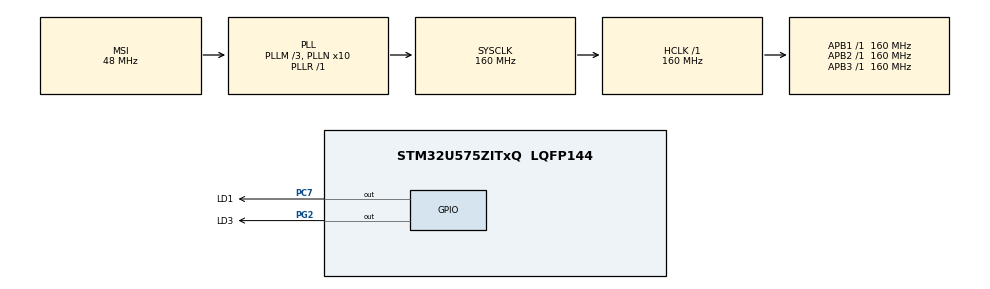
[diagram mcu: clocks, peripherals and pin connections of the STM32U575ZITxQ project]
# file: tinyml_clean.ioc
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CORTEX_M33_NS.userName=CORTEX_M33
Mcu.Family=STM32U5
Mcu.Name=STM32U575ZITxQ
Mcu.Package=LQFP144
NVIC.PriorityGroup=NVIC_PRIORITYGROUP_4
PC7.GPIO_Label=LD1
PC7.Signal=GPIO_Output
PG2.GPIO_Label=LD3
PG2.Signal=GPIO_Output
ProjectManager.HeapSize=0x800
ProjectManager.StackSize=0x800
ProjectManager.TargetToolchain=STM32CubeIDE
RCC.ADCCLockSelection=RCC_ADCDACCLKSOURCE_PLL2
RCC.ADCFreq_Value=160000000
RCC.AHBFreq_Value=160000000
RCC.APB1Freq_Value=160000000
RCC.APB1TimFreq_Value=160000000
RCC.APB2Freq_Value=160000000
RCC.APB2TimFreq_Value=160000000
RCC.APB3Freq_Value=160000000
RCC.CortexFreq_Value=160000000
RCC.EPOD_VALUE=48000000
RCC.HCLKFreq_Value=160000000
RCC.HSE_VALUE=16000000
RCC.HSI48_VALUE=48000000
RCC.HSI_VALUE=16000000
RCC.LSE_VALUE=32768
RCC.LSIDIV_VALUE=32000
RCC.MSIClockRange=RCC_MSIRANGE_0
RCC.MSI_VALUE=48000000
RCC.PLL1R=1
RCC.PLL2M=3
RCC.PLL2N=20
RCC.PLLM=3
RCC.PLLN=10
RCC.PWR_Regulator_Voltage_Scale=PWR_REGULATOR_VOLTAGE_SCALE1
RCC.SYSCLKFreq_VALUE=160000000
RCC.SYSCLKSource=RCC_SYSCLKSOURCE_PLLCLK
RCC.USBFreq_Value=48000000
RCC.VCOOutputFreq_Value=160000000
STMicroelectronics.X-CUBE-AI.10.2.0.ActivationBufferSizeList=2080
STMicroelectronics.X-CUBE-AI.10.2.0.ActivationBuffers=pool0
STMicroelectronics.X-CUBE-AI.10.2.0.ActivationNames=pool0
STMicroelectronics.X-CUBE-AI.10.2.0.ActivationSizes=AI_NETWORK_DATA_ACTIVATION_1_SIZE
STMicroelectronics.X-CUBE-AI.10.2.0.HeapSize=0x800
STMicroelectronics.X-CUBE-AI.10.2.0.InternalRamActivationBufferMaxSize=AI_NETWORK_DATA_ACTIVATIONS_SIZE
STMicroelectronics.X-CUBE-AI.10.2.0.MaximumNumberOfInputLayer=1
STMicroelectronics.X-CUBE-AI.10.2.0.MaximumNumberOfOutputLayer=1
STMicroelectronics.X-CUBE-AI.10.2.0.MaximumSizeOfInputLayer=1
STMicroelectronics.X-CUBE-AI.10.2.0.MaximumSizeOfOutputLayer=1
STMicroelectronics.X-CUBE-AI.10.2.0.ModelActualCompression-9a2e0019ac0026aa68c6628396b6957bef00fcc938f247decc194dd0d613c678=0.0
STMicroelectronics.X-CUBE-AI.10.2.0.ModelCompression-9a2e0019ac0026aa68c6628396b6957bef00fcc938f247decc194dd0d613c678=None
STMicroelectronics.X-CUBE-AI.10.2.0.ModelFlashOccupation-9a2e0019ac0026aa68c6628396b6957bef00fcc938f247decc194dd0d613c678=11228
STMicroelectronics.X-CUBE-AI.10.2.0.ModelHashList=9a2e0019ac0026aa68c6628396b6957bef00fcc938f247decc194dd0d613c678
STMicroelectronics.X-CUBE-AI.10.2.0.ModelKind-9a2e0019ac0026aa68c6628396b6957bef00fcc938f247decc194dd0d613c678=TFLITE
STMicroelectronics.X-CUBE-AI.10.2.0.ModelMacc-9a2e0019ac0026aa68c6628396b6957bef00fcc938f247decc194dd0d613c678=211
STMicroelectronics.X-CUBE-AI.10.2.0.ModelName-9a2e0019ac0026aa68c6628396b6957bef00fcc938f247decc194dd0d613c678=network
STMicroelectronics.X-CUBE-AI.10.2.0.ModelNameList=network
STMicroelectronics.X-CUBE-AI.10.2.0.ModelRamOccupation-9a2e0019ac0026aa68c6628396b6957bef00fcc938f247decc194dd0d613c678=2080
STMicroelectronics.X-CUBE-AI.10.2.0.ModelStructureFile-9a2e0019ac0026aa68c6628396b6957bef00fcc938f247decc194dd0d613c678=/Users/ilginkaya/Desktop/temp_model.tflite
STMicroelectronics.X-CUBE-AI.10.2.0.ModelType-9a2e0019ac0026aa68c6628396b6957bef00fcc938f247decc194dd0d613c678=STM32Cube.AI MCU runtime
STMicroelectronics.X-CUBE-AI.10.2.0.ReadyForCodeGeneration=true
STMicroelectronics.X-CUBE-AI.10.2.0.StackSize=0x800
STMicroelectronics.X-CUBE-AI.10.2.0.WorkingBufferStartAddrList=0xFFFFFFFF
STMicroelectronics.X-CUBE-AI.10.2.0.XAaCUBEAaAICcArtificialOoIntelligenceJjCore=true
STMicroelectronics.X-CUBE-AI.10.2.0.copyWeightToRam=false
STMicroelectronics.X-CUBE-AI.10.2.0.copyWeightToRam-9a2e0019ac0026aa68c6628396b6957bef00fcc938f247decc194dd0d613c678=false
STMicroelectronics.X-CUBE-AI.10.2.0.customLayerConfigEnabled=false
STMicroelectronics.X-CUBE-AI.10.2.0.customLayerConfigEnabled-9a2e0019ac0026aa68c6628396b6957bef00fcc938f247decc194dd0d613c678=false
STMicroelectronics.X-CUBE-AI.10.2.0.noOnnxIoTranspose=false
STMicroelectronics.X-CUBE-AI.10.2.0.noOnnxIoTranspose-9a2e0019ac0026aa68c6628396b6957bef00fcc938f247decc194dd0d613c678=false
STMicroelectronics.X-CUBE-AI.10.2.0.useInputAllocation=true
STMicroelectronics.X-CUBE-AI.10.2.0.useInputAllocation-9a2e0019ac0026aa68c6628396b6957bef00fcc938f247decc194dd0d613c678=true
STMicroelectronics.X-CUBE-AI.10.2.0.useOutputAllocation=true
STMicroelectronics.X-CUBE-AI.10.2.0.useOutputAllocation-9a2e0019ac0026aa68c6628396b6957bef00fcc938f247decc194dd0d613c678=true
VP_ICACHE_VS_ICACHE.Mode=DefaultMode
VP_LPBAMQUEUE_VS_QUEUE.Mode=QUEUEMODE
VP_LPBAM_VS_SIG1.Mode=SmartRun
VP_LPBAM_VS_SIG4.Mode=LPDMA1
VP_MEMORYMAP_VS_MEMORYMAP.Mode=CurAppReg
VP_PWR_VS_SECSignals.Mode=Security/Privilege
VP_STMicroelectronics.X-CUBE-AI_VS_ArtificialOoIntelligenceJjXAaCUBEAaAI_10.2.0.Mode=ArtificialOoIntelligenceJjXAaCUBEAaAI
board=custom

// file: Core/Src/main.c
/* USER CODE BEGIN Header */
/**
  ******************************************************************************
  * @file           : main.c
  * @brief          : Main program body
  ******************************************************************************
  */
/* USER CODE END Header */

#include "main.h"

/* USER CODE BEGIN Includes */
#include "network.h"
#include "network_data.h"
#include "ai_platform.h"
/* USER CODE END Includes */

/* USER CODE BEGIN PV */
ai_handle network = AI_HANDLE_NULL;

AI_ALIGNED(32)
static ai_u8 activations[AI_NETWORK_DATA_ACTIVATIONS_SIZE];

static float input_data[1];
static float output_data[1];
/* USER CODE END PV */

void SystemClock_Config(void);
static void MX_GPIO_Init(void);
static void MX_ICACHE_Init(void);

int main(void)
{
  HAL_Init();
  SystemClock_Config();
  MX_GPIO_Init();
  MX_ICACHE_Init();

  /* AI INIT */
  const ai_handle acts[] = { activations };
  ai_error err = ai_network_create_and_init(&network, acts, NULL);

  if (err.type != AI_ERROR_NONE)
  {
    Error_Handler();
  }

  while (1)
  {
    float sicaklik = 37.2f;   /* test için değiştir */

    /* Colab ile aynı normalizasyon */
    input_data[0] = (sicaklik - 36.0f) * 10.0f;

    ai_buffer *ai_input = ai_network_inputs_get(network, NULL);
    ai_buffer *ai_output = ai_network_outputs_get(network, NULL);

    ai_input[0].data = AI_HANDLE_PTR(input_data);
    ai_output[0].data = AI_HANDLE_PTR(output_data);

    if (ai_network_run(network, ai_input, ai_output) != 1)
    {
      Error_Handler();
    }

    /* output > 0.5 => normal */
    if (output_data[0] > 0.5f)
    {
      HAL_GPIO_WritePin(LD1_GPIO_Port, LD1_Pin, GPIO_PIN_SET);    /* yeşil ON */
      HAL_GPIO_WritePin(LD3_GPIO_Port, LD3_Pin, GPIO_PIN_RESET);  /* kırmızı OFF */
    }
    else
    {
      HAL_GPIO_WritePin(LD1_GPIO_Port, LD1_Pin, GPIO_PIN_RESET);  /* yeşil OFF */
      HAL_GPIO_WritePin(LD3_GPIO_Port, LD3_Pin, GPIO_PIN_SET);    /* kırmızı ON */
    }

    HAL_Delay(300);
  }
}

void SystemClock_Config(void)
{
  RCC_OscInitTypeDef RCC_OscInitStruct = {0};
  RCC_ClkInitTypeDef RCC_ClkInitStruct = {0};

  if (HAL_PWREx_ControlVoltageScaling(PWR_REGULATOR_VOLTAGE_SCALE1) != HAL_OK)
  {
    Error_Handler();
  }

  RCC_OscInitStruct.OscillatorType = RCC_OSCILLATORTYPE_MSI;
  RCC_OscInitStruct.MSIState = RCC_MSI_ON;
  RCC_OscInitStruct.MSICalibrationValue = RCC_MSICALIBRATION_DEFAULT;
  RCC_OscInitStruct.MSIClockRange = RCC_MSIRANGE_0;
  RCC_OscInitStruct.PLL.PLLState = RCC_PLL_ON;
  RCC_OscInitStruct.PLL.PLLSource = RCC_PLLSOURCE_MSI;
  RCC_OscInitStruct.PLL.PLLMBOOST = RCC_PLLMBOOST_DIV4;
  RCC_OscInitStruct.PLL.PLLM = 3;
  RCC_OscInitStruct.PLL.PLLN = 10;
  RCC_OscInitStruct.PLL.PLLP = 2;
  RCC_OscInitStruct.PLL.PLLQ = 2;
  RCC_OscInitStruct.PLL.PLLR = 1;
  RCC_OscInitStruct.PLL.PLLRGE = RCC_PLLVCIRANGE_1;
  RCC_OscInitStruct.PLL.PLLFRACN = 0;

  if (HAL_RCC_OscConfig(&RCC_OscInitStruct) != HAL_OK)
  {
    Error_Handler();
  }

  RCC_ClkInitStruct.ClockType = RCC_CLOCKTYPE_HCLK | RCC_CLOCKTYPE_SYSCLK
                              | RCC_CLOCKTYPE_PCLK1 | RCC_CLOCKTYPE_PCLK2
                              | RCC_CLOCKTYPE_PCLK3;
  RCC_ClkInitStruct.SYSCLKSource = RCC_SYSCLKSOURCE_PLLCLK;
  RCC_ClkInitStruct.AHBCLKDivider = RCC_SYSCLK_DIV1;
  RCC_ClkInitStruct.APB1CLKDivider = RCC_HCLK_DIV1;
  RCC_ClkInitStruct.APB2CLKDivider = RCC_HCLK_DIV1;
  RCC_ClkInitStruct.APB3CLKDivider = RCC_HCLK_DIV1;

  if (HAL_RCC_ClockConfig(&RCC_ClkInitStruct, FLASH_LATENCY_4) != HAL_OK)
  {
    Error_Handler();
  }
}

static void MX_ICACHE_Init(void)
{
  if (HAL_ICACHE_Enable() != HAL_OK)
  {
    Error_Handler();
  }
}

static void MX_GPIO_Init(void)
{
  GPIO_InitTypeDef GPIO_InitStruct = {0};

  __HAL_RCC_GPIOC_CLK_ENABLE();
  __HAL_RCC_GPIOG_CLK_ENABLE();

  HAL_GPIO_WritePin(LD1_GPIO_Port, LD1_Pin, GPIO_PIN_RESET);
  HAL_GPIO_WritePin(LD3_GPIO_Port, LD3_Pin, GPIO_PIN_RESET);

  /* LD1 - Green LED */
  GPIO_InitStruct.Pin = LD1_Pin;
  GPIO_InitStruct.Mode = GPIO_MODE_OUTPUT_PP;
  GPIO_InitStruct.Pull = GPIO_NOPULL;
  GPIO_InitStruct.Speed = GPIO_SPEED_FREQ_LOW;
  HAL_GPIO_Init(LD1_GPIO_Port, &GPIO_InitStruct);

  /* LD3 - Red LED */
  GPIO_InitStruct.Pin = LD3_Pin;
  HAL_GPIO_Init(LD3_GPIO_Port, &GPIO_InitStruct);
}

void Error_Handler(void)
{
  __disable_irq();
  while (1)
  {
  }
}
